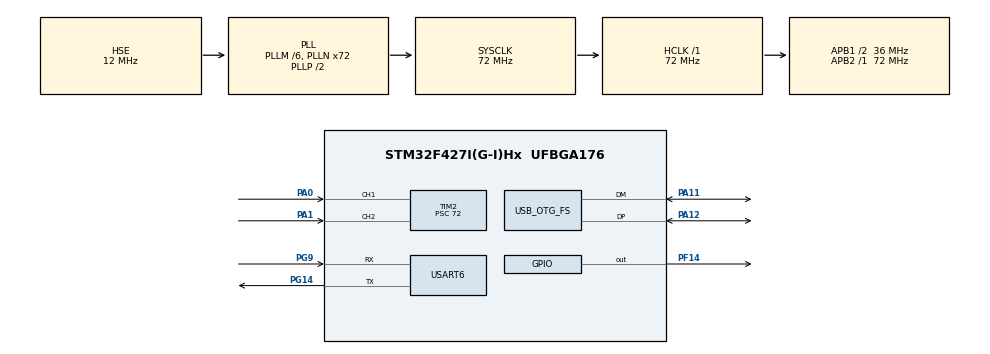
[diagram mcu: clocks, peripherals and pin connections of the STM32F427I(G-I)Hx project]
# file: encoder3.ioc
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Mcu.Family=STM32F4
Mcu.Name=STM32F427I(G-I)Hx
Mcu.Package=UFBGA176
NVIC.OTG_FS_IRQn=true\:0\:0\:false\:false\:true\:false\:true\:true
NVIC.PriorityGroup=NVIC_PRIORITYGROUP_4
NVIC.USART6_IRQn=true\:0\:0\:false\:false\:true\:true\:true\:true
PA0/WKUP.Signal=S_TIM2_CH1_ETR
PA1.Signal=S_TIM2_CH2
PA11.Mode=Device_Only
PA11.Signal=USB_OTG_FS_DM
PA12.Mode=Device_Only
PA12.Signal=USB_OTG_FS_DP
PF14.Signal=GPIO_Output
PG14.Mode=Asynchronous
PG14.Signal=USART6_TX
PG9.Mode=Asynchronous
PG9.Signal=USART6_RX
PH0/OSC_IN.Mode=HSE-External-Oscillator
PH0/OSC_IN.Signal=RCC_OSC_IN
PH1/OSC_OUT.Mode=HSE-External-Oscillator
PH1/OSC_OUT.Signal=RCC_OSC_OUT
ProjectManager.HeapSize=0x200
ProjectManager.StackSize=0x400
ProjectManager.TargetToolchain=MDK-ARM V5.32
RCC.48MHZClocksFreq_Value=48000000
RCC.AHBFreq_Value=72000000
RCC.APB1CLKDivider=RCC_HCLK_DIV2
RCC.APB1Freq_Value=36000000
RCC.APB1TimFreq_Value=72000000
RCC.APB2Freq_Value=72000000
RCC.APB2TimFreq_Value=72000000
RCC.CortexFreq_Value=72000000
RCC.HCLKFreq_Value=72000000
RCC.HSE_VALUE=12000000
RCC.HSI_VALUE=16000000
RCC.LSE_VALUE=32768
RCC.PLLM=6
RCC.PLLN=72
RCC.PLLQ=3
RCC.SYSCLKFreq_VALUE=72000000
RCC.SYSCLKSource=RCC_SYSCLKSOURCE_PLLCLK
RCC.VCOOutputFreq_Value=144000000
SH.S_TIM2_CH1_ETR.0=TIM2_CH1,Encoder_Interface
SH.S_TIM2_CH2.0=TIM2_CH2,Encoder_Interface
TIM2.AutoReloadPreload=TIM_AUTORELOAD_PRELOAD_ENABLE
TIM2.EncoderMode=TIM_ENCODERMODE_TI12
TIM2.IC1Filter=6
TIM2.IC2Filter=6
TIM2.Period=65535
TIM2.Prescaler=72
USART6.VirtualMode=VM_ASYNC
USB_DEVICE.CLASS_NAME_FS=CDC
USB_DEVICE.VirtualMode-CDC_FS=Cdc
USB_DEVICE.VirtualModeFS=Cdc_FS
USB_OTG_FS.VirtualMode=Device_Only
VP_USB_DEVICE_VS_USB_DEVICE_CDC_FS.Mode=CDC_FS
board=custom

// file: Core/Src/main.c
/* USER CODE BEGIN Header */
/**
  ******************************************************************************
  * @file           : main.c
  * @brief          : Main program body
  ******************************************************************************
  * @attention
  *
  * Copyright (c) 2023 STMicroelectronics.
  * All rights reserved.
  *
  * This software is licensed under terms that can be found in the LICENSE file
  * in the root directory of this software component.
  * If no LICENSE file comes with this software, it is provided AS-IS.
  *
  ******************************************************************************
  */
/* USER CODE END Header */
#include "main.h"
#include "tim.h"
#include "usart.h"
#include "usb_device.h"
#include "gpio.h"

/* USER CODE BEGIN Includes */
#include <stdio.h>
#include "usbd_cdc_if.h"

/* USER CODE END Includes */

void SystemClock_Config(void);

/* USER CODE BEGIN 0 */
int TIMcnt;

int GetTimEncoder(void)//获取TIM4定时器读出来的编码器脉冲
{
		int cnt;//存放从TIM4定时器读出来的编码器脉冲
    cnt = (short)(__HAL_TIM_GET_COUNTER(&htim2));//先读取脉冲数
    __HAL_TIM_SET_COUNTER(&htim2,0);//再计数器清零
    return cnt;//返回脉冲数
}
/* USER CODE END 0 */

int main(void)
{

  /* MCU Configuration--------------------------------------------------------*/

  /* Reset of all peripherals, Initializes the Flash interface and the Systick. */
  HAL_Init();

  /* Configure the system clock */
  SystemClock_Config();

  /* Initialize all configured peripherals */
  MX_GPIO_Init();
  MX_USART6_UART_Init();
  MX_TIM2_Init();
  MX_USB_DEVICE_Init();
  /* USER CODE BEGIN 2 */
	HAL_TIM_Encoder_Start(&htim2, TIM_CHANNEL_ALL);//开启TIM4的编码器接口模式
  /* USER CODE END 2 */

  /* Infinite loop */
  /* USER CODE BEGIN WHILE */
  while (1)
  {
		HAL_Delay(500);
		TIMcnt = GetTimEncoder();//捕获TIM4脉冲数据
		//uint8_t data[]="来了 \n";
		//CDC_Transmit_FS(data,sizeof(data));//直接调用usb的函数输出
		//printf("TIM2定时器编码器模式捕获脉冲 = %d \n",TIMcnt);//把脉冲数据打印出来
		USBVcom_printf("TIM2定时器编码器模式捕获脉冲 = %d \n",TIMcnt);//调用重定向后的usb打印函数
		HAL_GPIO_TogglePin(GPIOF,GPIO_PIN_14);
    /* USER CODE END WHILE */

  }
}

void SystemClock_Config(void)
{
  RCC_OscInitTypeDef RCC_OscInitStruct = {0};
  RCC_ClkInitTypeDef RCC_ClkInitStruct = {0};

  /** Configure the main internal regulator output voltage
  */
  __HAL_RCC_PWR_CLK_ENABLE();
  __HAL_PWR_VOLTAGESCALING_CONFIG(PWR_REGULATOR_VOLTAGE_SCALE3);

  /** Initializes the RCC Oscillators according to the specified parameters
  * in the RCC_OscInitTypeDef structure.
  */
  RCC_OscInitStruct.OscillatorType = RCC_OSCILLATORTYPE_HSE;
  RCC_OscInitStruct.HSEState = RCC_HSE_ON;
  RCC_OscInitStruct.PLL.PLLState = RCC_PLL_ON;
  RCC_OscInitStruct.PLL.PLLSource = RCC_PLLSOURCE_HSE;
  RCC_OscInitStruct.PLL.PLLM = 6;
  RCC_OscInitStruct.PLL.PLLN = 72;
  RCC_OscInitStruct.PLL.PLLP = RCC_PLLP_DIV2;
  RCC_OscInitStruct.PLL.PLLQ = 3;
  if (HAL_RCC_OscConfig(&RCC_OscInitStruct) != HAL_OK)
  {
    Error_Handler();
  }

  /** Initializes the CPU, AHB and APB buses clocks
  */
  RCC_ClkInitStruct.ClockType = RCC_CLOCKTYPE_HCLK|RCC_CLOCKTYPE_SYSCLK
                              |RCC_CLOCKTYPE_PCLK1|RCC_CLOCKTYPE_PCLK2;
  RCC_ClkInitStruct.SYSCLKSource = RCC_SYSCLKSOURCE_PLLCLK;
  RCC_ClkInitStruct.AHBCLKDivider = RCC_SYSCLK_DIV1;
  RCC_ClkInitStruct.APB1CLKDivider = RCC_HCLK_DIV2;
  RCC_ClkInitStruct.APB2CLKDivider = RCC_HCLK_DIV1;

  if (HAL_RCC_ClockConfig(&RCC_ClkInitStruct, FLASH_LATENCY_2) != HAL_OK)
  {
    Error_Handler();
  }
}

void Error_Handler(void)
{
  __disable_irq();
  while (1)
  {
  }
}
